# MINI58DE_v1 register map
File version: 1.0
Registers are 32-bit, read-write, reset 0x0 unless marked. A register's access mark holds for its fields unless they carry their own. Offsets are from the block's base; [hi:lo] are bit positions; {n}, {i} and the like mark numbered series; 'fields as' and 'values as' point back to an identical list.

## PWM0 — PWM0 Register Map
Base 0x40040000
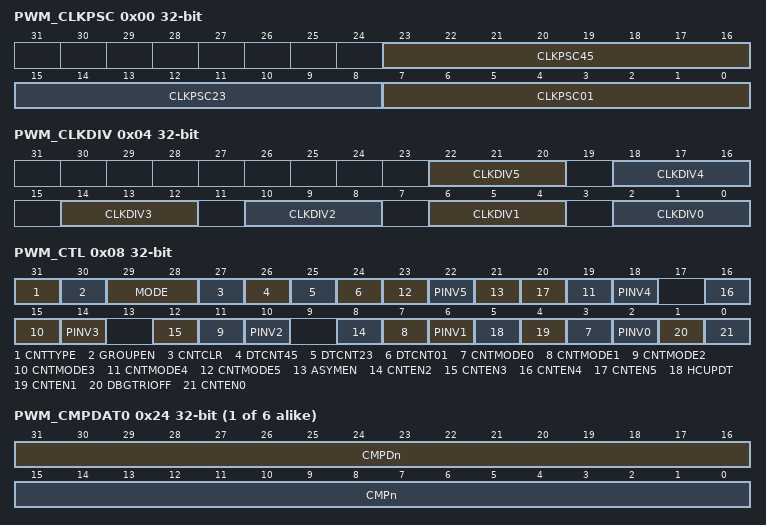
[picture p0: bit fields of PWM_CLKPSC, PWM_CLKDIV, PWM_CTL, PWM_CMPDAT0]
0x00 PWM_CLKPSC — PWM Clock Pre-scale Register
  [23:16] CLKPSC45 — Clock Prescaler 4 For PWM Counter 4 And 5. Clock input is divided by (CLKPSC45 + 1) before it is fed to the corresponding PWM counter.
  [15:8] CLKPSC23 — Clock Prescaler 2 For PWM Counter 2 And 3. Clock input is divided by (CLKPSC23 + 1) before it is fed to the corresponding PWM counter.
  [7:0] CLKPSC01 — Clock Prescaler 0 For PWM Counter 0 And 1. Clock input is divided by (CLKPSC01 + 1) before it is fed to the corresponding PWM counter.
0x04 PWM_CLKDIV — PWM Clock Select Register
  [22:20] CLKDIV5 — Counter 5 Clock Divider Selection. Select clock input for PWM counter.
    0=Clock input / (CLKPSC45/2); 1=Clock input / (CLKPSC45/4); 2=Clock input / (CLKPSC45/8); 3=Clock input / (CLKPSC45/16); 4=Clock input / CLKPSC45
  [18:16] CLKDIV4 — Counter 4 Clock Divider Selection. Select clock input for PWM counter.
    values as CLKDIV5
  [14:12] CLKDIV3 — Counter 3 Clock Divider Selection. Select clock input for PWM counter.
    0=Clock input / (CLKPSC23/2); 1=Clock input / (CLKPSC23/4); 2=Clock input / (CLKPSC23/8); 3=Clock input / (CLKPSC23/16); 4=Clock input / CLKPSC23
  [10:8] CLKDIV2 — Counter 2 Clock Divider Selection. Select clock input for PWM counter.
    values as CLKDIV3
  [6:4] CLKDIV1 — Counter 1 Clock Divider Selection. Select clock input for PWM counter.
    0=Clock input / (CLKPSC01/2); 1=Clock input / (CLKPSC01/4); 2=Clock input / (CLKPSC01/8); 3=Clock input / (CLKPSC01/16); 4=Clock input / CLKPSC01
  [2:0] CLKDIV0 — Counter 0 Clock Divider Selection. Select clock input for PWM counter.
    values as CLKDIV1
0x08 PWM_CTL — PWM Control Register
  [31] CNTTYPE — PWM Counter-aligned Type Select Bit
    0=Edge-aligned type; 1=Center-aligned type
  [30] GROUPEN — Group Function Enable Bit
    0=The signals timing of all PWM channels are independent; 1=Unify the signals timing of PWM0_CH0, PWM0_CH2 and PWM0_CH4 in the same phase which is controlled by PWM0_CH0 and also unify the signals timing of PWM0_CH1, PWM0_CH3 and PWM0_CH5 in the same phase which is controlled by PWM0_CH1
  [29:28] MODE — PWM Operating Mode Select Bit
    0=Independent mode; 1=Complementary mode; 2=Synchronized mode
  [27] CNTCLR — Clear PWM Counter Control Bit. Note: It is automatically cleared by hardware.
    0=Do not clear PWM counter; 1=All 16-bit PWM counters cleared to 0x0000
  [26] DTCNT45 — Dead-time 4 Counter Enable Bit (PWM0_CH4 And PWM0_CH5 Pair For PWMC Group). Note: When the dead-time generator is enabled, the pair of PWM0_CH4 and PWM0_CH5 becomes a complementary pair for PWMC group.
    0=Dead-time 4 generator Disabled; 1=Dead-time 4 generator Enabled
  [25] DTCNT23 — Dead-time 2 Counter Enable Bit (PWM0_CH2 And PWM0_CH3 Pair For PWMB Group). Note: When the dead-time generator is enabled, the pair of PWM0_CH2 and PWM0_CH3 becomes a complementary pair for PWMB group.
    0=Dead-time 2 generator Disabled; 1=Dead-time 2 generator Enabled
  [24] DTCNT01 — Dead-time 0 Counter Enable Bit (PWM0_CH0 And PWM0_CH1 Pair For PWMA Group). Note: When the dead-time generator is enabled, the pair of PWM0_CH0 and PWM0_CH1 becomes a complementary pair for PWMA group.
    0=Dead-time 0 generator Disabled; 1=Dead-time 0 generator Enabled
  [4n+3] CNTMODE{n} (n=0..5) — PWM Counter {n} Auto-reload/One-shot Mode. Note: If there is a rising transition at this bit, it will cause PERIOD{n} and CMP{n} cleared.
    0=One-shot mode; 1=Auto-reload mode
  [22] PINV5 — PWM0_CH5 Output Inverter Enable Bit
    0=PWM0_CH5 output inverter Disabled; 1=PWM0_CH5 output inverter Enabled
  [21] ASYMEN — Asymmetric Mode In Center-aligned Type
    0=Symmetric mode in center-aligned type; 1=Asymmetric mode in center-aligned type
  [4n] CNTEN{n} (n=2..5) — PWM Counter {n} Enable Start Run
    0=Corresponding PWM counter running Stopped; 1=Corresponding PWM counter start run Enabled
  [18] PINV4 — PWM0_CH4 Output Inverter Enable Bit
    0=PWM0_CH4 output inverter Disabled; 1=PWM0_CH4 output inverter Enabled
  [14] PINV3 — PWM0_CH 3 Output Inverter Enable Bit
    0=PWM0_CH3 output inverter Disabled; 1=PWM0_CH3 output inverter Enabled
  [10] PINV2 — PWM0_CH2 Output Inverter Enable Bit
    0=PWM0_CH2 output inverter Disabled; 1=PWM0_CH2 output inverter Enabled
  [6] PINV1 — PWM0_CH1 Output Inverter Enable Bit
    0=PWM0_CH1 output inverter Disable; 1=PWM0_CH1 output inverter Enable
  [5] HCUPDT — Half Cycle Update Enable for Center-aligned Type
    0=Disable half cycle update PERIOD CMP; 1=Enable half cycle update PERIOD CMP
  [4] CNTEN1 — PWM Counter 1 Enable/Disable Start Run
    values as CNTEN2
  [2] PINV0 — PWM0_CH0 Output Inverter Enable Bit
    0=PWM0_CH0 output inverter Disabled; 1=PWM0_CH0 output inverter Enabled
  [1] DBGTRIOFF — Disable PWM Output Tri-state Under Debug Mode (Available In DEBUG Mode Only)
    0=Safe mode: The counter is frozen and PWM outputs are shut down Safe state for the inverter. The counter can still be re-started from where it stops; 1=Normal mode: The counter continues to operate normally May be dangerous in some cases since a constant duty cycle is applied to the inverter (no more interrupts serviced)
  [0] CNTEN0 — PWM Counter 0 Enable Start Run
    values as CNTEN2
{0xC+4i} PWM_PERIOD{i} (i=0..5) — PWM Counter Period Register {i}
  [15:0] PERIODn — PWM Counter Period Value. PERIODn determines the PWM counter period. Edge-aligned type: Note: Any write to PERIODn will take effect in the next PWM cycle.
{0x24+4i} PWM_CMPDAT{i} (i=0..5) — PWM Comparator Register {i}
  [31:16] CMPDn — PWM Comparator Register For Down Counter In Asymmetric Mode. Others: PWM output is always high.
  [15:0] CMPn — PWM Comparator Register. CMP determines the PWM duty. Edge-aligned type: Note: Any write to CMPn will take effect in the next PWM cycle.
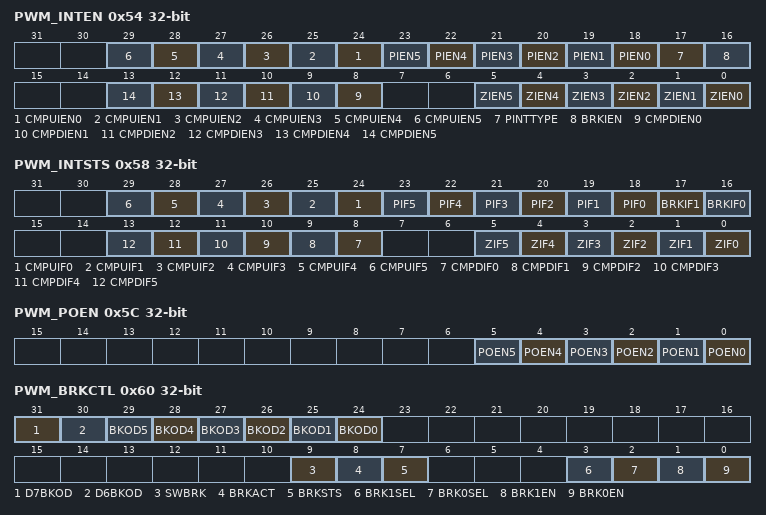
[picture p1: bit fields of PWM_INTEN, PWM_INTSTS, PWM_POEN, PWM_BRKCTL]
0x54 PWM_INTEN — PWM Interrupt Enable Register
  [n+24] CMPUIEN{n} (n=0..5) — PWM Compare Up Interrupt Enable Bit
    0=PWM0_CHn compare up interrupt Disabled; 1=PWM0_CHn compare up interrupt Enabled
  [n+18] PIEN{n} (n=0..5) — PWM Period Interrupt Enable Bit
    0=PWM0_CHn period interrupt Disabled; 1=PWM0_CHn period interrupt Enabled
  [17] PINTTYPE — PWM Interrupt Type Selection. Note: This bit is effective when PWM is in center-aligned type only.
    0=ZIFn will be set if PWM counter underflows; 1=ZIFn will be set if PWM counter matches PERIODn register
  [16] BRKIEN — Fault Brake0 And Fault Brake1 Interrupt Enable Bit
    0=BRKIF0 and BRKIF1 trigger PWM interrupt Disabled; 1=BRKIF0 and BRKIF1 trigger PWM interrupt Enabled
  [n+8] CMPDIEN{n} (n=0..5) — PWM Compare Down Interrupt Enable Bit
    0=PWM0_CHn compare down interrupt Disabled; 1=PWM0_CHn compare down interrupt Enabled
  [n] ZIEN{n} (n=0..5) — PWM Zero Point Interrupt Enable Bit
    0=PWM0_CHn zero point interrupt Disabled; 1=PWM0_CHn zero point interrupt Enabled
0x58 PWM_INTSTS — PWM Interrupt Status Register
  [n+24] CMPUIF{n} (n=0..5) — PWM Compare Up Interrupt Flag. Flag is set by hardware when PWM0_CHn counter up count reaches CMPn. Note: This bit can be cleared by software writing 1.
  [n+18] PIF{n} (n=0..5) — PWM Period Interrupt Flag. Flag is set by hardware when PWM0_CHn counter reaches PERIODn. Note: This bit can be cleared by software writing 1.
  [17] BRKIF1 — PWM Brake1 Flag. Note: This bit can be cleared by software writing 1.
    0=PWM Brake does not recognize a falling signal at BKP1; 1=When PWM Brake detects a falling signal at pin BKP1; this flag will be set to high
  [16] BRKIF0 — PWM Brake0 Flag. Note: This bit can be cleared by software writing 1.
    0=PWM Brake does not recognize a falling signal at BKP0; 1=When PWM Brake detects a falling signal at pin BKP0; this flag will be set to high
  [n+8] CMPDIF{n} (n=0..5) — PWM Compare Down Interrupt Flag. Flag is set by hardware when PWMn counter downcount reaches CMPn. Note: This bit can be cleared by software writing 1.
  [n] ZIF{n} (n=0..5) — PWM Zero Point Interrupt Flag. Flag is set by hardware when PWMn counter downcount reaches zero point. Note: This bit can be cleared by software writing 1.
0x5C PWM_POEN — PWM Output Enable Register
  [all] fields
    0=PWM channel n output to pin Disabled; 1=PWM channel n output to pin Enabled
  [n] POEN{n} (n=0..5) — PWM Output Enable Bits. Note: The corresponding GPIO pin must be switched to PWM function.
0x60 PWM_BRKCTL — PWM Fault Brake Control Register
  [31] D7BKOD — Channel 7 Brake Output Data Select Bit
    0=Channel 7 output low when fault brake conditions asserted; 1=Channel 7 output high when fault brake conditions asserted
  [30] D6BKOD — Channel 6 Brake Output Data Select Bit
    0=Channel 6 output low when fault brake conditions asserted; 1=Channel 6 output high when fault brake conditions asserted
  [n+24] BKOD{n} (n=0..5) — PWM Brake Output Data Select Bits
    0=PWM channel n output low when fault brake conditions asserted; 1=PWM channel n output high when fault brake conditions asserted
  [9] SWBRK — Software Brake
    0=Disable PWM Software brake and back to normal PWM function; 1=Assert PWM Brake immediately
  [8] BRKACT — PWM Brake Action Type
    0=PWM counter stop when brake is asserted; 1=PWM counter keep going when brake is asserted
  [7] BRKSTS — PWM Fault Brake Event Status Flag. Note: This bit can be cleared by software writing 1 and must be cleared before restarting the PWM counter.
    0=PWM output initial state when fault brake conditions asserted; 1=PWM output fault brake state when fault brake conditions asserted
  [3] BRK1SEL — BKP0 Fault Brake Function Source Select Bit
    0=EINT0 as one brake source in BKP0; 1=CPO1 as one brake source in BKP0
  [2] BRK0SEL — BKP1 Fault Brake Function Source Select Bit
    0=EINT1 as one brake source in BKP1; 1=CPO0 as one brake source in BKP1
  [1] BRK1EN — Enable BKP1 Pin Trigger Fault Brake Function 1
    0=Disabling BKP1 pin can trigger brake function 1 (EINT1 or CPO0); 1=Enabling a falling at BKP1 pin can trigger brake function 1
  [0] BRK0EN — Enable BKP0 Pin Trigger Fault Brake Function 0
    0=Disabling BKP0 pin can trigger brake function 0 (EINT0 or CPO1); 1=Enabling a falling at BKP0 pin can trigger brake function 0
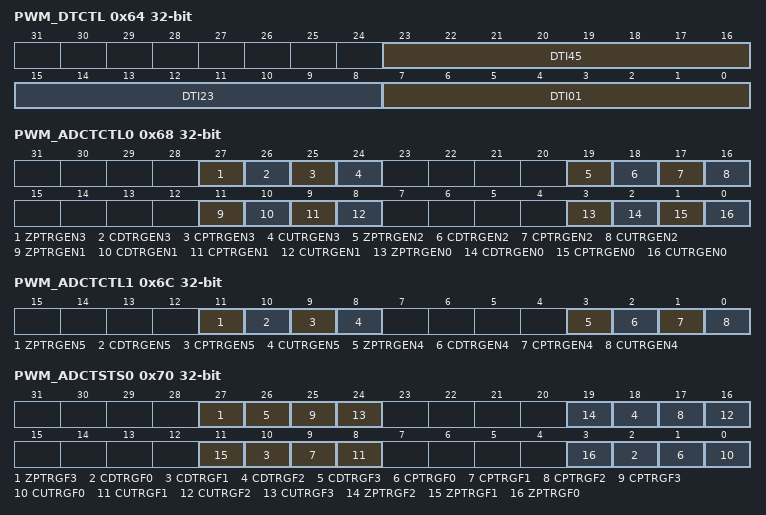
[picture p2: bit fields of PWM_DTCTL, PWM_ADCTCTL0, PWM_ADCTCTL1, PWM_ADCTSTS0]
0x64 PWM_DTCTL — PWM Dead-time Control Register
  [23:16] DTI45 — Dead-time Interval Register For Pair Of Channel4 And Channel5 (PWM0_CH4 And PWM0_CH5 Pair). These 8 bits determine dead-time length. The unit time of dead-time length is received from corresponding PWM_CLKDIV bits.
  [15:8] DTI23 — Dead-time Interval Register For Pair Of Channel2 And Channel3 (PWM0_CH2 And PWM0_CH3 Pair). These 8 bits determine dead-time length. The unit time of dead-time length is received from corresponding PWM_CLKDIV bits.
  [7:0] DTI01 — Dead-time Interval Register For Pair Of Channel0 And Channel1 (PWM0_CH0 And PWM0_CH1 Pair). These 8 bits determine dead-time length. The unit time of dead-time length is received from corresponding PWM_CLKDIV bits.
0x68 PWM_ADCTCTL0 — PWM Trigger Control Register 0
  [all] fields
    0=PWM condition trigger ADC function Disabled; 1=PWM condition trigger ADC function Enabled
  [27] ZPTRGEN3 — Channel 3 Zero Point Trigger ADC Enable Bit. Enable PWM trigger ADC function while channel3's counter matching 0. Note: This bit is valid for both center-aligned type and edged aligned type.
  [26] CDTRGEN3 — Channel 3 Compare Down Trigger ADC Enable Bit. Enable PWM trigger ADC function while channel3's counter matching CMP3 in down-count direction. Note: This bit is valid for both center-aligned type and edged aligned type.
  [25] CPTRGEN3 — Channel 3 Center Point Trigger ADC Enable Bit. Enable PWM trigger ADC function while channel3's counter matching PERIOD3. Note: This bit is only valid for PWM in center-aligned type. When PWM is in edged aligned type, setting this bit is meaningless and will not take any effect.
  [24] CUTRGEN3 — Channel 3 Compare Up Trigger ADC Enable Bit. Enable PWM trigger ADC function while channel3's counter matching CMP3 in up-count direction. Note: This bit is only valid for PWM in center-aligned type. When PWM is in edged aligned type, setting this bit is meaningless and will not take any effect.
  [19] ZPTRGEN2 — Channel 2 Zero Point Trigger ADC Enable Bit. Enable PWM trigger ADC function while channel2's counter matching 0. Note: This bit is valid for both center-aligned type and edged-aligned type.
  [18] CDTRGEN2 — Channel 2 Compare Down Trigger ADC Enable Bit. Enable PWM trigger ADC function while channel2's counter matching CMP2 in down-count direction. Note: This bit is valid for both center-aligned type and edged-aligned type.
  [17] CPTRGEN2 — Channel 2 Center Point Trigger ADC Enable Bit. Enable PWM trigger ADC function while channel2's counter matching PERIOD2. Note: This bit is only valid for PWM in center-aligned type. When PWM is in edged-aligned type, setting this bit is meaningless and will not take any effect.
  [16] CUTRGEN2 — Channel 2 Compare Up Trigger ADC Enable Bit. Enable PWM trigger ADC function while channel2's counter matching CMP2 in up-count direction. Note: This bit is only valid for PWM in center-aligned type. When PWM is in edged-aligned type, setting this bit is meaningless and will not take any effect.
  [11] ZPTRGEN1 — Channel 1 Zero Point Trigger ADC Enable Bit. Enable PWM trigger ADC function While channel1's Counter Matching 0. Note: This bit is valid for both center-aligned type and edged-aligned type.
  [10] CDTRGEN1 — Channel 1 Compare Down Trigger ADC Enable Bit. Enable PWM trigger ADC function while channel1's counter matching CMP1 in down-count direction. Note: This bit is valid for both center-aligned type and edged-aligned type.
  [9] CPTRGEN1 — Channel 1 Center Point Trigger ADC Enable Bit. Enable PWM trigger ADC function while channel1's counter matching PERIOD1. Note: This bit is only valid for PWM in center-aligned type. When PWM is in edged-aligned type, setting this bit is meaningless and will not take any effect.
  [8] CUTRGEN1 — Channel 1 Compare Up Trigger ADC Enable Bit. Enable PWM trigger ADC function while channel1's counter matching CMP1 in up-count direction. Note: This bit is only valid for PWM in center-aligned type. When PWM is in edged-aligned type, setting this bit is meaningless and will not take any effect.
  [3] ZPTRGEN0 — Channel 0 Zero Point Trigger ADC Enable Bit. Enable PWM trigger ADC function while channel0's counter matching 0. Note: This bit is valid for both center-aligned type and edged-aligned type.
  [2] CDTRGEN0 — Channel 0 Compare Down Trigger ADC Enable Bit. Enable PWM trigger ADC function while channel0's counter matching CMP0 in down-count direction. Note: This bit is valid for both center-aligned type and edged-aligned type.
  [1] CPTRGEN0 — Channel 0 Center Point Trigger ADC Enable Bit. Enable PWM Trigger ADC Function While channel0's Counter Matching PERIOD0. Note: This bit is only valid for PWM in center-aligned type. When PWM is in edged-aligned type, setting this bit is meaningless and will not take any effect.
  [0] CUTRGEN0 — Channel 0 Compare Up Trigger ADC Enable Bit. Enable PWM trigger ADC function while channel0's counter matching CMP0 in up-count direction. Note: This bit is only valid for PWM in center-aligned type. When PWM is in edged-aligned type, setting this bit is meaningless and will not take any effect.
0x6C PWM_ADCTCTL1 — PWM Trigger Control Register 1
  [all] fields
    values as the fields of PWM_ADCTCTL0
  [11] ZPTRGEN5 — Channel 5 Zero Point Trigger ADC Enable Bit. Enable PWM trigger ADC function while channel5's counter matching 0. Note: This bit is valid for both center-aligned type and edged-aligned type.
  [10] CDTRGEN5 — Channel 5 Compare Down Trigger ADC Enable Bit. Enable PWM trigger ADC function while channel5's counter matching CMP5 in down-count direction. Note: This bit is valid for both center-aligned type and edged-aligned type.
  [9] CPTRGEN5 — Channel 5 Center Point Trigger ADC Enable Bit. Enable PWM trigger ADC function while channel5's counter matching PERIOD5. Note: This bit is only valid for PWM in center-aligned type. When PWM is in edged-aligned type, setting this bit is meaningless and will not take any effect.
  [8] CUTRGEN5 — Channel 5 Compare Up Trigger ADC Enable Bit. Enable PWM trigger ADC function while channel5's counter matching CMP5 in up-count direction. Note: This bit is only valid for PWM in center-aligned type. When PWM is in edged-aligned type, setting this bit is meaningless and will not take any effect.
  [3] ZPTRGEN4 — Channel 4 Zero Point Trigger ADC Enable Bit. Enable PWM trigger ADC function while channel4's counter matching 0. Note: This bit is valid for both center-aligned type and edged-aligned type.
  [2] CDTRGEN4 — Channel 4 Compare Down Trigger ADC Enable Bit. Enable PWM trigger ADC function while channel4's counter matching CMP4 in down-count direction. Note: This bit is valid for both center-aligned type and edged-aligned type.
  [1] CPTRGEN4 — Channel 4 Center Point Trigger ADC Enable Bit. Enable PWM trigger ADC function while channel4's counter matching PERIOD4. Note: This bit is only valid for PWM in center-aligned type. When PWM is in edged-aligned type, setting this bit is meaningless and will not take any effect.
  [0] CUTRGEN4 — Channel 4 Compare Up Trigger ADC Enable Bit. Enable PWM trigger ADC function while channel4's counter matching CMP4 in up-count direction. Note: This bit is only valid for PWM in center-aligned type. When PWM is in edged-aligned type, setting this bit is meaningless and will not take any effect.
0x70 PWM_ADCTSTS0 — PWM Trigger Status Register 0
  [27] ZPTRGF3 — Channel 3 Zero Point Trigger ADC Flag. When the channel3's counter is counting to zero point, this bit will be set for trigger ADC. Note: This bit can be cleared by software writing 1.
  [8n+2] CDTRGF{n} (n=0..3) — Channel {n} Compare Down Trigger ADC Flag. When the channel{n}'s counter is counting down to CMP{n}, this bit will be set for trigger ADC. Note: This bit can be cleared by software writing 1.
  [8n+1] CPTRGF{n} (n=0..3) — Channel {n} Center Point Trigger ADC Flag. When the channel{n}'s counter is counting to PERIOD{n}, this bit will be set for trigger ADC. Note: This bit can be cleared by software writing 1.
  [8n] CUTRGF{n} (n=0..3) — Channel {n} Compare Up Trigger ADC Flag. When the channel{n}'s counter is counting up to CMP{n}, this bit will be set for trigger ADC. Note: This bit can be cleared by software writing 1.
  [19] ZPTRGF2 — Channel 2 Zero Point Trigger ADC Enable Bit. When the channel2's counter is counting to zero point, this bit will be set for trigger ADC. Note: This bit can be cleared by software writing 1.
  [11] ZPTRGF1 — Channel 1 Zero Point Trigger ADC Flag. When the channel1's counter is counting to zero point, this bit will be set for trigger ADC. Note: This bit can be cleared by software writing 1.
  [3] ZPTRGF0 — Channel 0 Zero Point Trigger ADC Flag. When the channel0's counter is counting to zero point, this bit will be set for trigger ADC. Note: This bit can be cleared by software writing 1.
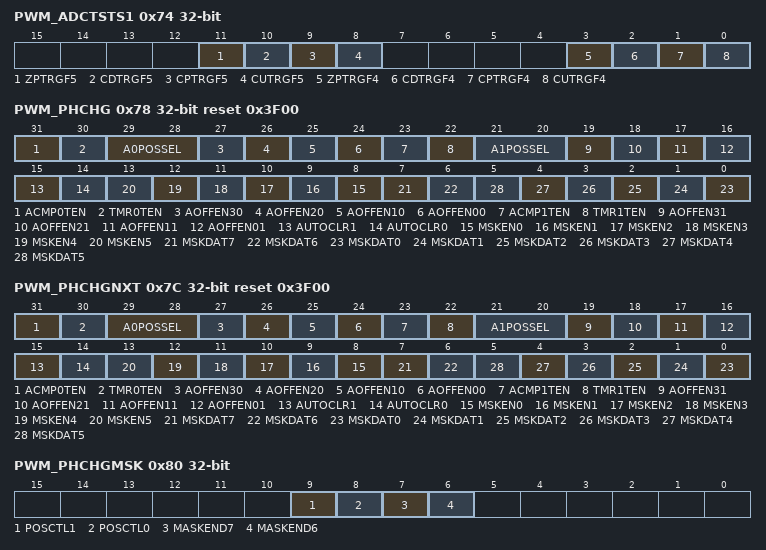
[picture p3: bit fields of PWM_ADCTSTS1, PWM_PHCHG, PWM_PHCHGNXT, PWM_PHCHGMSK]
0x74 PWM_ADCTSTS1 — PWM Trigger Status Register 1
  [11] ZPTRGF5 — Channel 5 Zero Point Trigger ADC Flag. When the channel5's counter is counting to zero point, this bit will be set for trigger ADC. Note: This bit can be cleared by software writing 1.
  [10] CDTRGF5 — Channel 5 Compare Down Trigger ADC Flag. When the channel5's counter is counting down to CMP5, this bit will be set for trigger ADC. Note: This bit can be cleared by software writing 1.
  [9] CPTRGF5 — Channel 5 Center Point Trigger ADC Flag. When the channel5's counter is counting to PERIOD5, this bit will be set for trigger ADC. Note: This bit can be cleared by software writing 1.
  [8] CUTRGF5 — Channel 5 Compare Up Trigger ADC Flag. When the channel5's counter is counting up to CMP5, this bit will be set for trigger ADC. Note: This bit can be cleared by software writing 1.
  [3] ZPTRGF4 — Channel 4 Zero Point Trigger ADC Flag. When the channel4's counter is counting to zero point, this bit will be set for trigger ADC. Note: This bit can be cleared by software writing 1.
  [2] CDTRGF4 — Channel 4 Compare Down Trigger ADC Flag. When the channel4's counter is counting down to CMP4, this bit will be set for trigger ADC. Note: This bit can be cleared by software writing 1.
  [1] CPTRGF4 — Channel 4 Center Point Trigger ADC Flag. When the channel4's counter is counting to PERIOD4, this bit will be set for trigger ADC. Note: This bit can be cleared by software writing 1.
  [0] CUTRGF4 — Channel 4 Compare Up Trigger ADC Flag. When the channel4's counter is counting up to CMP4, this bit will be set for trigger ADC. Note: This bit can be cleared by software writing 1.
0x78 PWM_PHCHG reset 0x3F00 — PWM Phase Changed Register
  [31] ACMP0TEN — ACMP0 Trigger PWM Function Enable Bit. Note: This bit will be auto cleared when ACMP0 trigger PWM if AUTOCLR0 is set.
    0=ACMP0 trigger PWM function Disabled; 1=ACMP0 trigger PWM function Enabled
  [30] TMR0TEN — TIMER0 Trigger PWM Function Enable Bit. When this bit is set, TIMER0 time-out event will update PWM_PHCHG with PHCHG_NXT register.
    0=TIMER0 trigger PWM function Disabled; 1=TIMER0 trigger PWM function Enabled
  [29:28] A0POSSEL — ACMP0 Positive Input Source Select Bits
    0=Select P1.5 as the input of ACMP0; 1=Select P1.0 as the input of ACMP0; 2=Select P1.2 as the input of ACMP0; 3=Select P1.3 as the input of ACMP0
  [27] AOFFEN30 — ACMP0 Trigger Channel 3 One Cycle Output Off Enable Bit. Setting this bit will force PWM channel 3 to output low lasting for at most one period cycle as long as ACMP0 trigger It; This feature is usually in step motor application. Note: This function is only available for PWM0_CH0~ PWM0_CH3.
    0=PWM0_CH3 one period cycle output low Disabled; 1=PWM0_CH3 one period cycle output low Enabled
  [26] AOFFEN20 — ACMP0 Trigger Channel 2 One Cycle Output Off Enable Bit. Setting this bit will force PWM channel 2 to output low lasting for at most one period cycle as long as ACMP0 trigger It; This feature is usually in step motor application. Note: This function is only available for PWM0_CH0~PWM0_CH3.
    0=PWM0_CH2 one period cycle output low Disabled; 1=PWM0_CH2 one period cycle output low Enabled
  [25] AOFFEN10 — ACMP0 Trigger Channel 1 One Cycle Output Off Enable Bit. Setting this bit will force PWM channel 1 to output low lasting for at most one period cycle as long as ACMP0 trigger It; This feature is usually in step motor application. Note: This function is only available for PWM0_CH0~PWM0_CH3.
    0=PWM0_CH1 one period cycle output low Disabled; 1=PWM0_CH1 one period cycle output low Enabled
  [24] AOFFEN00 — ACMP0 Trigger Channel 0 One Cycle Output Off Enable Bit. Setting this bit will force PWM channel 0 to output low lasting for at most one period cycle as long as ACMP0 trigger It; This feature is usually in step motor application. Note: This function is only available for PWM0_CH0~PWM0_CH3.
    0=PWM0_CH0 one period cycle output low Disabled; 1=PWM0_CH0 one period cycle output low Enabled
  [23] ACMP1TEN — ACMP1 Trigger Function Enable Bit. Note: This bit will be auto cleared when ACMP1 trigger PWM if AUTOCLR1 is set.
    0=ACMP1 trigger PWM function Disabled; 1=ACMP1 trigger PWM function Enabled
  [22] TMR1TEN — TIMER1 Trigger PWM Function Enable Bit. When this bit is set, TIMER1 time-out event will update PWM_PHCHG with PHCHG_NXT register.
    0=TIMER1 trigger PWM function Disabled; 1=TIMER1 trigger PWM function Enabled
  [21:20] A1POSSEL — ACMP1 Positive Input Source Select Bits
    0=Select P3.1 as the input of ACMP1; 1=Select P3.2 as the input of ACMP1; 2=Select P3.3 as the input of ACMP1; 3=Select P3.4 as the input of ACMP1
  [19] AOFFEN31 — ACMP1 Trigger Channel 3 One Cycle Output Off Enable Bit. Setting this bit will force PWM channel 3 to output low lasting for at most one period cycle as long as ACMP1 trigger It; This feature is usually in step motor application. Note: This function is only available for PWM0_CH0~PWM0_CH3.
    values as AOFFEN30
  [18] AOFFEN21 — ACMP1 Trigger Channel 2 One Cycle Output Off Enable Bit. Setting this bit will force PWM channel 2 to output low lasting for at most one period cycle as long as ACMP1 trigger It; This feature is usually in step motor application. Note: This function is only available for PWM0_CH0~PWM0_CH 3.
    values as AOFFEN20
  [17] AOFFEN11 — ACMP1 Trigger Channel 1 One Cycle Output Off Enable Bit. Setting this bit will force PWM channel 1 to output low lasting for at most one period cycle as long as ACMP1 trigger It; This feature is usually in step motor application. Note: This function is only available for PWM0_CH0~PWM0_CH3.
    values as AOFFEN10
  [16] AOFFEN01 — ACMP1 Trigger Channel 0 One Cycle Output Off Enable Bit. Setting this bit will force PWM channel 0 to output low lasting for at most one period cycle as long as ACMP1 trigger It; This feature is usually in step motor application. Note: This function is only available for PWM0_CH0~PWM0_CH3.
    values as AOFFEN00
  [15] AUTOCLR1 — Hardware Auto Clear ACMP1TEN
    0=Hardware will auto clear ACMP1TEN when ACMP1 trigger PWM; 1=Hardware will not auto clear ACMP1TEN when ACMP1 trigger PWM
  [14] AUTOCLR0 — Hardware Auto Clear ACMP0TEN
    0=Hardware will auto clear ACMP0TEN when ACMP0 trigger PWM; 1=Hardware will not auto clear ACMP0TEN when ACMP0 trigger PWM
  [n+8] MSKEN{n} (n=0..5) — PWMn Output Mask Enable Bits
    0=Output MSKDATn specified in bit n of PWM_PHCHG register; 1=Output the original channel n waveform
  [7] MSKDAT7 — PWM0_CH7 (GPIO P0.0) Mask Data. When MASKEND7 Is 1, channel 7's output level is MSKDAT7.
    0=PWM0_CH7 output low level; 1=PWM0_CH7 output high level
  [6] MSKDAT6 — PWM0_CH6 (GPIO P0.1) Mask Data. When MASKEND6 Is 1, channel 6's output level is MSKDAT6.
    0=PWM0_CH6 output low level; 1=PWM0_CH6 output high level
  [n] MSKDAT{n} (n=0..5) — PWM0_CHn Mask Data. When MSKENn is 0, channel n's output level is MSKDATn.
    0=PWM0_CHn output low level; 1=PWM0_CHn output high level
0x7C PWM_PHCHGNXT reset 0x3F00 — PWM Next Phase Change Register
  [31] ACMP0TEN — ACMP0 Trigger Function Enable Bit. Note: This bit will be auto cleared when ACMP0 trigger PWM if AUTOCLR0 is set.
    values as PWM_PHCHG.ACMP0TEN
  [30] TMR0TEN — TMR0 Trigger PWM Function Enable Bit. When this bit is set, TMR0 time-out event will update PWM_PHCHG with PHCHG_NXT register.
    0=TMR0 trigger PWM function Disabled; 1=TMR0 trigger PWM function Enabled
  [29:28] A0POSSEL — ACMP0 Positive Input Source Select Bits
    values as PWM_PHCHG.A0POSSEL
  [27] AOFFEN30 — ACMP0 Trigger Channel 3 One Cycle Output Off Enable Bit. Setting this bit will force PWM channel 3 to output low lasting for at most one period cycle as long as ACMP0 trigger It; This feature is usually in step motor application. Note: This function is only available for PWM0_CH0~PWM0_CH3.
    values as PWM_PHCHG.AOFFEN30
  [26] AOFFEN20 — ACMP0 Trigger Channel 2 One Cycle Output Off Enable Bit. Setting this bit will force PWM channel 2 to output low lasting for at most one period cycle as long as ACMP0 trigger It; This feature is usually in step motor application. Note: This function is only available for PWM0_CH0~PWM0_CH3.
    values as PWM_PHCHG.AOFFEN20
  [25] AOFFEN10 — ACMP0 Trigger Channel 1 One Cycle Output Off Enable Bit. Setting this bit will force PWM channel 1 to output low lasting for at most one period cycle as long as ACMP0 trigger It; This feature is usually in step motor application. Note: This function is only available for PWM0_CH0~PWM0_CH3.
    values as PWM_PHCHG.AOFFEN10
  [24] AOFFEN00 — ACMP0 Trigger Channel 0 One Cycle Output Off Enable Bit. Setting this bit will force PWM channel 0 to output low lasting for at most one period cycle as long as ACMP0 trigger It; This feature is usually in step motor application. Note: This function is only available for PWM0_CH0~PWM0_CH3.
    values as PWM_PHCHG.AOFFEN00
  [23] ACMP1TEN — ACMP1 Trigger Function Enable Bit. Note: This bit will be auto cleared when ACMP1 trigger PWM if AUTOCLR1 is set.
    values as PWM_PHCHG.ACMP1TEN
  [22] TMR1TEN — TMR1 Trigger PWM Function Enable Bit. When this bit is set, TMR1 time-out event will update PWM_PHCHG with PHCHG_NXT register.
    0=TMR1 trigger PWM function Disabled; 1=TMR1 trigger PWM function Enabled
  [21:20] A1POSSEL — ACMP1 Positive Input Source Select Bits
    values as PWM_PHCHG.A1POSSEL
  [19] AOFFEN31 — ACMP1 Trigger Channel 3 One Cycle Output Off Enable Bit. Setting this bit will force PWM channel 3 to output low lasting for at most one period cycle as long as ACMP1 trigger It; This feature is usually in step motor application. Note: This function is only available for PWM0_CH0~PWM0_CH3.
    values as PWM_PHCHG.AOFFEN30
  [18] AOFFEN21 — ACMP1 Trigger Channel 2 One Cycle Output Off Enable Bit. Setting this bit will force PWM channel 2 to output low lasting for at most one period cycle as long as ACMP1 trigger It; This feature is usually in step motor application. Note: This function is only available for PWM0_CH0~PWM0_CH3.
    values as PWM_PHCHG.AOFFEN20
  [17] AOFFEN11 — ACMP1 Trigger Channel 1 One Cycle Output Off Enable Bit. Setting this bit will force PWM channel 1 to output low lasting for at most one period cycle as long as ACMP1 trigger It; This feature is usually in step motor application. Note: This function is only available for PWM0_CH0~PWM0_CH3.
    values as PWM_PHCHG.AOFFEN10
  [16] AOFFEN01 — ACMP1 Trigger Channel 0 One Cycle Output Off Enable Bit. Setting this bit will force PWM channel 0 to output low lasting for at most one period cycle as long as ACMP1 trigger It; This feature is usually in step motor application. Note: This function is only available for PWM0_CH0~PWM0_CH3.
    values as PWM_PHCHG.AOFFEN00
  [15] AUTOCLR1 — Hardware Auto Clear ACMP1TEN
    values as PWM_PHCHG.AUTOCLR1
  [14] AUTOCLR0 — Hardware Auto Clear ACMP0TEN
    values as PWM_PHCHG.AUTOCLR0
  [n+8] MSKEN{n} (n=0..5) — PWM Output Mask Enable Bits
    values as PWM_PHCHG.MSKEN0
  [7] MSKDAT7 — PWM0_CH7 (GPIO P0.0) Mask Data. When MASKEND7 Is 1, channel 7's output level is MSKDAT7.
    0=PWM0_CH7 output low level; 1=PWM0_CH7 output high level
  [6] MSKDAT6 — PWM0_CH6 (GPIO P0.1) Mask Data. When MASKEND6 Is 1, channel 6's output level is MSKDAT6.
    0=PWM0_CH6 output low level; 1=PWM0_CH6 output high level
  [n] MSKDAT{n} (n=0..5) — PWM0_CHn Mask Data. When MSKENn is 0, channel n's output level is MSKDATn.
    0=PWM0_CHn output low level; 1=PWM0_CHn output high level
0x80 PWM_PHCHGMSK — PWM Phase Change Mask Register
  [9] POSCTL1 — Positive Input Control For ACMP1. Note: Register CMP1CR is described in Comparator Controller chapter.
    0=The input of ACMP is controlled by CMP1CR; 1=The input of ACMP is controlled by CMP1SEL of PWM_PHCHG register
  [8] POSCTL0 — Positive Input Control For ACMP0. Note: Register CMP0CR is described in Comparator Controller chapter.
    0=The input of ACMP is controlled by CMP0CR; 1=The input of ACMP is controlled by CMP0SEL of PWM_PHCHG register
  [7] MASKEND7 — PWM0_CH7 (GPIO P0.0) Output Mask Enable Bit
    0=Output the original GPIO P0.0; 1=Output MSKDAT7 specified in bit 7 of PWM_PHCHG register
  [6] MASKEND6 — PWM0_CH6 (GPIO P0.1) Output Mask Enable Bit
    0=Output the original GPIO P0.1; 1=Output MSKDAT6 specified in bit 6 of PWM_PHCHG register
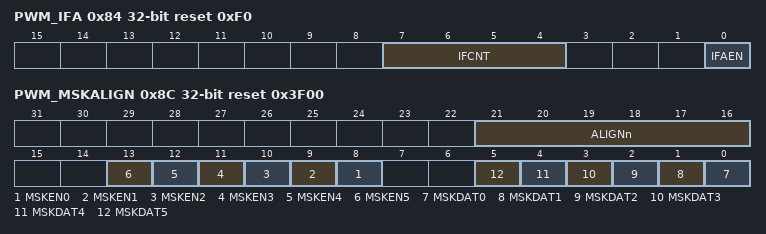
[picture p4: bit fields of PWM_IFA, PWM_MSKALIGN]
0x84 PWM_IFA reset 0xF0 — PWM Period Interrupt Accumulation Control Register
  [7:4] IFCNT — Interrupt Accumulation Counter. When IFAEN is set, IFCNT will decrease when every ZIFn flag is set and when IFCNT reach to zero, the PWMn interrupt will occurred and IFCNT will reload itself.
  [0] IFAEN — Interrupt Accumulation Function Enable Bit
    0=Interrupt accumulation function Disabled; 1=Interrupt accumulation function Enabled
0x88 PWM_PCACTL — PWM Precise Center-aligned Type Control Register
  [0] PCAEN — PWM Precise Center-aligned Type Enable Bit
    0=Precise center-aligned type Disabled; 1=Precise center-aligned type Enabled
0x8C PWM_MSKALIGN reset 0x3F00 — PWM Phase Change Mask Aligned Register
  [21:16] ALIGNn — PWM0_CHn Output Mask Aligned Enable Bit
    0=PWM0_CHn output will mask immediately when mask function enabled; 1=PWM0_CHn output will mask when output aligned to PWM period
  [n+8] MSKEN{n} (n=0..5) — PWM Output Mask Enable Bits
    values as PWM_PHCHG.MSKEN0
  [n] MSKDAT{n} (n=0..5) — PWM0_CHn Mask Data. When MSKENn is 0, channel n's output level is MSKDATn.
    0=PWM0_CHn output low level; 1=PWM0_CHn output high level
